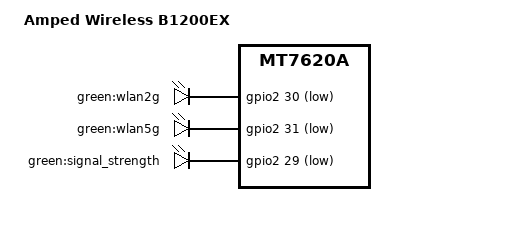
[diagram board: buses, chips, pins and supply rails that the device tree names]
// SPDX-License-Identifier: GPL-2.0-or-later OR MIT

#include "mt7620a_edimax_ew-747x.dtsi"

/ {
	compatible = "ampedwireless,b1200ex", "ralink,mt7620a-soc";
	model = "Amped Wireless B1200EX";

	leds {
		wlan2g {
			label = "green:wlan2g";
			gpios = <&gpio2 30 GPIO_ACTIVE_LOW>;
			linux,default-trigger = "phy1radio";
		};

		wlan5g {
			label = "green:wlan5g";
			gpios = <&gpio2 31 GPIO_ACTIVE_LOW>;
			linux,default-trigger = "phy0radio";
		};

		signal_strength {
			label = "green:signal_strength";
			gpios = <&gpio2 29 GPIO_ACTIVE_LOW>;
		};
	};
};
